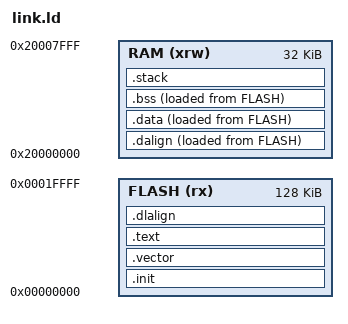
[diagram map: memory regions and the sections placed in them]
ENTRY( _start )

__stack_size = 4096;

PROVIDE( _stack_size = __stack_size );


MEMORY
{
/* CH32V30x_D8C - CH32V305RB-CH32V305FB
   CH32V30x_D8 - CH32V303CB-CH32V303RB
*/
	FLASH (rx) : ORIGIN = 0x00000000, LENGTH = 128K
	RAM (xrw) : ORIGIN = 0x20000000, LENGTH = 32K
    
/* CH32V30x_D8C - CH32V307VC-CH32V307WC-CH32V307RC
   CH32V30x_D8 - CH32V303VC-CH32V303RC
   FLASH + RAM supports the following configuration
   FLASH-192K + RAM-128K
   FLASH-224K + RAM-96K
   FLASH-256K + RAM-64K  
   FLASH-288K + RAM-32K  
*/
/*
	FLASH (rx) : ORIGIN = 0x00000000, LENGTH = 288K
	RAM (xrw) : ORIGIN = 0x20000000, LENGTH = 32K
*/
}


SECTIONS
{
	.init :
	{
		_sinit = .;
		. = ALIGN(4);
		KEEP(*(SORT_NONE(.init)))
		. = ALIGN(4);
		_einit = .;
	} >FLASH AT>FLASH

	 .vector :
	 {
		 *(.vector);
		 . = ALIGN(64);
	 } >FLASH AT>FLASH

	.text :
	{
		. = ALIGN(4);
		*(.text)
		*(.text.*)
		*(.rodata)
		*(.rodata*)
		*(.gnu.linkonce.t.*)
		. = ALIGN(4);
	} >FLASH AT>FLASH 

	PROVIDE( _etext = . );
	PROVIDE( _eitcm = . );

	.dalign :
	{
		. = ALIGN(4);
		PROVIDE(_data_vma = .);
	} >RAM AT>FLASH	

	.dlalign :
	{
		. = ALIGN(4); 
		PROVIDE(_data_lma = .);
	} >FLASH AT>FLASH

	.data :
	{
    	*(.gnu.linkonce.r.*)
    	*(.data .data.*)
    	*(.gnu.linkonce.d.*)
		. = ALIGN(8);
    	PROVIDE( __global_pointer$ = . + 0x800 );
    	*(.sdata .sdata.*)
		*(.sdata2.*)
    	*(.gnu.linkonce.s.*)
    	. = ALIGN(8);
    	*(.srodata.cst16)
    	*(.srodata.cst8)
    	*(.srodata.cst4)
    	*(.srodata.cst2)
    	*(.srodata .srodata.*)
    	. = ALIGN(4);
		PROVIDE( _edata = .);
	} >RAM AT>FLASH

	.bss :
	{
		. = ALIGN(4);
		PROVIDE( _sbss = .);
  	    *(.sbss*)
        *(.gnu.linkonce.sb.*)
		*(.bss*)
     	*(.gnu.linkonce.b.*)		
		*(COMMON*)
		. = ALIGN(4);
		PROVIDE( _ebss = .);
	} >RAM AT>FLASH

	PROVIDE( _end = _ebss);
	PROVIDE( end = . );

    .stack ORIGIN(RAM) + LENGTH(RAM) - __stack_size :
    {
        PROVIDE( _heap_end = . );    
        . = ALIGN(4);
        PROVIDE(_susrstack = . );
        . = . + __stack_size;
        PROVIDE( _eusrstack = .);
    } >RAM
}
